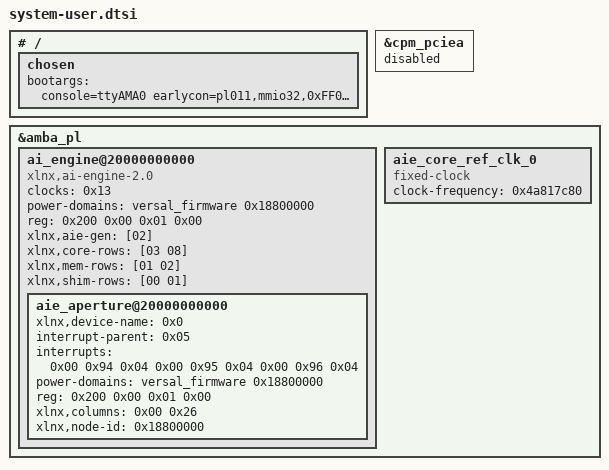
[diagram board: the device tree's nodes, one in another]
#/*
#Copyright (C) 2023, Advanced Micro Devices, Inc. All rights reserved.
#SPDX-License-Identifier: MIT
#*/

/ {
chosen {
   bootargs = "console=ttyAMA0 earlycon=pl011,mmio32,0xFF000000,115200n8 clk_ignore_unused root=/dev/mmcblk0p2 rw rootwait cma=512M";
      };
   };

&cpm_pciea {
	status = "disabled";
};

&amba_pl {

	ai_engine@20000000000 {
		#address-cells = <0x02>;
		#size-cells = <0x02>;
		clock-names = "aclk0";
		clocks = <0x13>;
		compatible = "xlnx,ai-engine-2.0\0xlnx,ai-engine-v2.0";
		power-domains = <&versal_firmware 0x18800000>;
		ranges;
		reg = <0x200 0x00 0x01 0x00>;
		xlnx,aie-gen = [02];
		xlnx,core-rows = [03 08];
		xlnx,mem-rows = [01 02];
		xlnx,shim-rows = [00 01];

		aie_aperture@20000000000 {
			#address-cells = <0x02>;
			#size-cells = <0x02>;
			xlnx,device-name = <0x0>;
			interrupt-names = "interrupt1\0interrupt2\0interrupt3";
			interrupt-parent = <0x05>;
			interrupts = <0x00 0x94 0x04 0x00 0x95 0x04 0x00 0x96 0x04>;
			power-domains = <&versal_firmware 0x18800000>;
			reg = <0x200 0x00 0x01 0x00>;
			xlnx,columns = <0x00 0x26>;
			xlnx,node-id = <0x18800000>;
		};
	};
	aie_core_ref_clk_0 {
		#clock-cells = <0x00>;
                clock-frequency = <0x4a817c80>;
		compatible = "fixed-clock";
		phandle = <0x13>;
	};
	
};
